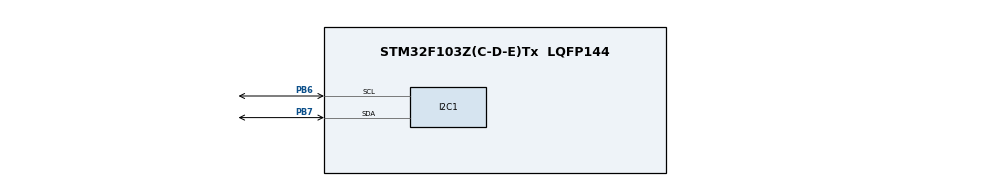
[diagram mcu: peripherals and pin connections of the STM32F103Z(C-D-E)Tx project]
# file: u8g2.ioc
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Mcu.Family=STM32F1
Mcu.Name=STM32F103Z(C-D-E)Tx
Mcu.Package=LQFP144
NVIC.PriorityGroup=NVIC_PRIORITYGROUP_4
PA13.Mode=JTAG_5_pins
PA13.Signal=SYS_JTMS-SWDIO
PA14.Mode=JTAG_5_pins
PA14.Signal=SYS_JTCK-SWCLK
PA15.Mode=JTAG_5_pins
PA15.Signal=SYS_JTDI
PB3.Mode=JTAG_5_pins
PB3.Signal=SYS_JTDO-TRACESWO
PB4.Mode=JTAG_5_pins
PB4.Signal=SYS_NJTRST
PB6.Mode=I2C
PB6.Signal=I2C1_SCL
PB7.Mode=I2C
PB7.Signal=I2C1_SDA
ProjectManager.HeapSize=0x4000
ProjectManager.StackSize=0x8000
ProjectManager.TargetToolchain=Makefile
RCC.APB1Freq_Value=8000000
RCC.APB2Freq_Value=8000000
board=custom

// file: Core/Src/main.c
/* USER CODE BEGIN Header */
/**
  ******************************************************************************
  * @file           : main.c
  * @brief          : Main program body
  ******************************************************************************
  * @attention
  *
  * <h2><center>&copy; Copyright (c) 2022 STMicroelectronics.
  * All rights reserved.</center></h2>
  *
  * This software component is licensed by ST under BSD 3-Clause license,
  * the "License"; You may not use this file except in compliance with the
  * License. You may obtain a copy of the License at:
  *                        opensource.org/licenses/BSD-3-Clause
  *
  ******************************************************************************
  */
/* USER CODE END Header */
#include "main.h"
#include "i2c.h"
#include "gpio.h"

/* USER CODE BEGIN Includes */
#include "oled.h"
/* USER CODE END Includes */

void SystemClock_Config(void);

int main(void)
{

  /* MCU Configuration--------------------------------------------------------*/

  /* Reset of all peripherals, Initializes the Flash interface and the Systick. */
  HAL_Init();

  /* Configure the system clock */
  SystemClock_Config();

  /* Initialize all configured peripherals */
  MX_GPIO_Init();
  MX_I2C1_Init();
  /* USER CODE BEGIN 2 */

  u8g2_t u8g2;
  u8g2Init (&u8g2);
  /* USER CODE END 2 */

  /* Infinite loop */
  /* USER CODE BEGIN WHILE */
  while (1)
  {
    u8g2_SendBuffer(&u8g2);
    u8g2_DrawBox(&u8g2,0,0,20,20);
    u8g2_DrawBox(&u8g2,20,20,20,20);
    u8g2_SendBuffer(&u8g2);
    u8g2_DrawFrame(&u8g2,10,40,20,20);
    u8g2_SendBuffer(&u8g2);
    u8g2_SetFont(&u8g2,u8g2_font_DigitalDiscoThin_tf);
    u8g2_DrawStr(&u8g2,30,10,"free");
    u8g2_SendBuffer(&u8g2);

    HAL_Delay(1000);
    /* USER CODE END WHILE */

  }
}

void SystemClock_Config(void)
{
  RCC_OscInitTypeDef RCC_OscInitStruct = {0};
  RCC_ClkInitTypeDef RCC_ClkInitStruct = {0};

  /** Initializes the RCC Oscillators according to the specified parameters
  * in the RCC_OscInitTypeDef structure.
  */
  RCC_OscInitStruct.OscillatorType = RCC_OSCILLATORTYPE_HSI;
  RCC_OscInitStruct.HSIState = RCC_HSI_ON;
  RCC_OscInitStruct.HSICalibrationValue = RCC_HSICALIBRATION_DEFAULT;
  RCC_OscInitStruct.PLL.PLLState = RCC_PLL_NONE;
  if (HAL_RCC_OscConfig(&RCC_OscInitStruct) != HAL_OK)
  {
    Error_Handler();
  }
  /** Initializes the CPU, AHB and APB buses clocks
  */
  RCC_ClkInitStruct.ClockType = RCC_CLOCKTYPE_HCLK|RCC_CLOCKTYPE_SYSCLK
                              |RCC_CLOCKTYPE_PCLK1|RCC_CLOCKTYPE_PCLK2;
  RCC_ClkInitStruct.SYSCLKSource = RCC_SYSCLKSOURCE_HSI;
  RCC_ClkInitStruct.AHBCLKDivider = RCC_SYSCLK_DIV1;
  RCC_ClkInitStruct.APB1CLKDivider = RCC_HCLK_DIV1;
  RCC_ClkInitStruct.APB2CLKDivider = RCC_HCLK_DIV1;

  if (HAL_RCC_ClockConfig(&RCC_ClkInitStruct, FLASH_LATENCY_0) != HAL_OK)
  {
    Error_Handler();
  }
}

void Error_Handler(void)
{
  __disable_irq();
  while (1)
  {
  }
}

/************************ (C) COPYRIGHT STMicroelectronics *****END OF FILE****/
